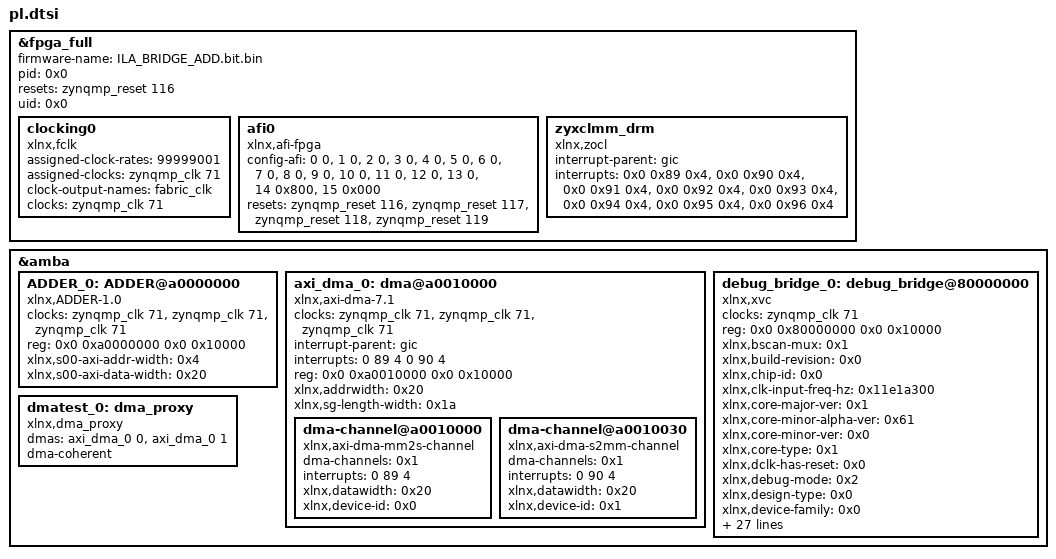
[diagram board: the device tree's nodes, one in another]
/*
 * CAUTION: This file is automatically generated by Xilinx.
 * Version: XSCT 2024.1
 * Today is: Fri Aug 22 16:06:07 2025
 */


/dts-v1/;
/plugin/;
&fpga_full {
	firmware-name = "ILA_BRIDGE_ADD.bit.bin";
	pid = <0x0>;
	resets = <&zynqmp_reset 116>;
	uid = <0x0>;
	clocking0: clocking0 {
		#clock-cells = <0>;
		assigned-clock-rates = <99999001>;
		assigned-clocks = <&zynqmp_clk 71>;
		clock-output-names = "fabric_clk";
		clocks = <&zynqmp_clk 71>;
		compatible = "xlnx,fclk";
	};
	afi0: afi0 {
		compatible = "xlnx,afi-fpga";
		config-afi = < 0 0>, <1 0>, <2 0>, <3 0>, <4 0>, <5 0>, <6 0>, <7 0>, <8 0>, <9 0>, <10 0>, <11 0>, <12 0>, <13 0>, <14 0x800>, <15 0x000>;
		resets = <&zynqmp_reset 116>, <&zynqmp_reset 117>, <&zynqmp_reset 118>, <&zynqmp_reset 119>;
	};
	zyxclmm_drm {
		compatible = "xlnx,zocl";
		interrupt-parent = <&gic>;
		interrupts = <0x0 0x89 0x4>, <0x0 0x90 0x4>, <0x0 0x91 0x4>, <0x0 0x92 0x4>, <0x0 0x93 0x4>, <0x0 0x94 0x4>, <0x0 0x95 0x4>, <0x0 0x96 0x4>;
	};
};
&amba {
	#address-cells = <2>;
	#size-cells = <2>;
	ADDER_0: ADDER@a0000000 {
		/* This is a place holder node for a custom IP, user may need to update the entries */
		clock-names = "m00_axis_aclk", "s00_axi_aclk", "s00_axis_aclk";
		clocks = <&zynqmp_clk 71>, <&zynqmp_clk 71>, <&zynqmp_clk 71>;
		compatible = "xlnx,ADDER-1.0";
		reg = <0x0 0xa0000000 0x0 0x10000>;
		xlnx,s00-axi-addr-width = <0x4>;
		xlnx,s00-axi-data-width = <0x20>;
	};
	axi_dma_0: dma@a0010000 {
		#dma-cells = <1>;
		clock-names = "m_axi_mm2s_aclk", "m_axi_s2mm_aclk", "s_axi_lite_aclk";
		clocks = <&zynqmp_clk 71>, <&zynqmp_clk 71>, <&zynqmp_clk 71>;
		compatible = "xlnx,axi-dma-7.1", "xlnx,axi-dma-1.00.a";
		interrupt-names = "mm2s_introut", "s2mm_introut";
		interrupt-parent = <&gic>;
		interrupts = <0 89 4 0 90 4>;
		reg = <0x0 0xa0010000 0x0 0x10000>;
		xlnx,addrwidth = <0x20>;
		xlnx,sg-length-width = <0x1a>;
		dma-channel@a0010000 {
			compatible = "xlnx,axi-dma-mm2s-channel";
			dma-channels = <0x1>;
			interrupts = <0 89 4>;
			xlnx,datawidth = <0x20>;
			xlnx,device-id = <0x0>;
		};
		dma-channel@a0010030 {
			compatible = "xlnx,axi-dma-s2mm-channel";
			dma-channels = <0x1>;
			interrupts = <0 90 4>;
			xlnx,datawidth = <0x20>;
			xlnx,device-id = <0x1>;
		};
	};
	debug_bridge_0: debug_bridge@80000000 {
		clock-names = "s_axi_aclk";
		clocks = <&zynqmp_clk 71>;
		compatible = "xlnx,debug-bridge-3.0", "generic-uio";
		reg = <0x0 0x80000000 0x0 0x10000>;
		xlnx,bscan-mux = <0x1>;
		xlnx,build-revision = <0x0>;
		xlnx,chip-id = <0x0>;
		xlnx,clk-input-freq-hz = <0x11e1a300>;
		xlnx,core-major-ver = <0x1>;
		xlnx,core-minor-alpha-ver = <0x61>;
		xlnx,core-minor-ver = <0x0>;
		xlnx,core-type = <0x1>;
		xlnx,dclk-has-reset = <0x0>;
		xlnx,debug-mode = <0x2>;
		xlnx,design-type = <0x0>;
		xlnx,device-family = <0x0>;
		xlnx,en-bscanid-vec = "false";
		xlnx,en-int-sim = <0x1>;
		xlnx,en-passthrough = <0x0>;
		xlnx,enable-clk-divider = "false";
		xlnx,fifo-style = "SUBCORE";
		xlnx,ir-id-instr = <0x0>;
		xlnx,ir-user1-instr = <0x0>;
		xlnx,ir-width = <0x0>;
		xlnx,major-version = <0xe>;
		xlnx,master-intf-type = <0x1>;
		xlnx,minor-version = <0x1>;
		xlnx,num-bs-master = <0x0>;
		xlnx,pcie-ext-cfg-base-addr = <0x400>;
		xlnx,pcie-ext-cfg-next-ptr = <0x000>;
		xlnx,pcie-ext-cfg-vsec-id = <0x0008>;
		xlnx,pcie-ext-cfg-vsec-length = <0x020>;
		xlnx,pcie-ext-cfg-vsec-rev-id = <0x0>;
		xlnx,tck-clock-ratio = <0x8>;
		xlnx,two-prim-mode = "false";
		xlnx,use-bufr = <0x0>;
		xlnx,use-ext-bscan = "true";
		xlnx,use-softbscan = <0x1>;
		xlnx,use-startup-clk = "false";
		xlnx,user-scan-chain = <0x1>;
		xlnx,xsdb-num-slaves = <0x0>;
		xlnx,xvc-hw-id = <0x0001>;
		xlnx,xvc-sw-id = <0x0001>;
	};
	dmatest_0: dma_proxy {
			compatible ="xlnx,dma_proxy";
			dmas = <&axi_dma_0 0 &axi_dma_0 1>;
			dma-names = "dma_proxy_tx", "dma_proxy_rx";
			dma-coherent;
	};
};
&debug_bridge_0 {
        compatible = "xlnx,xvc";
};
